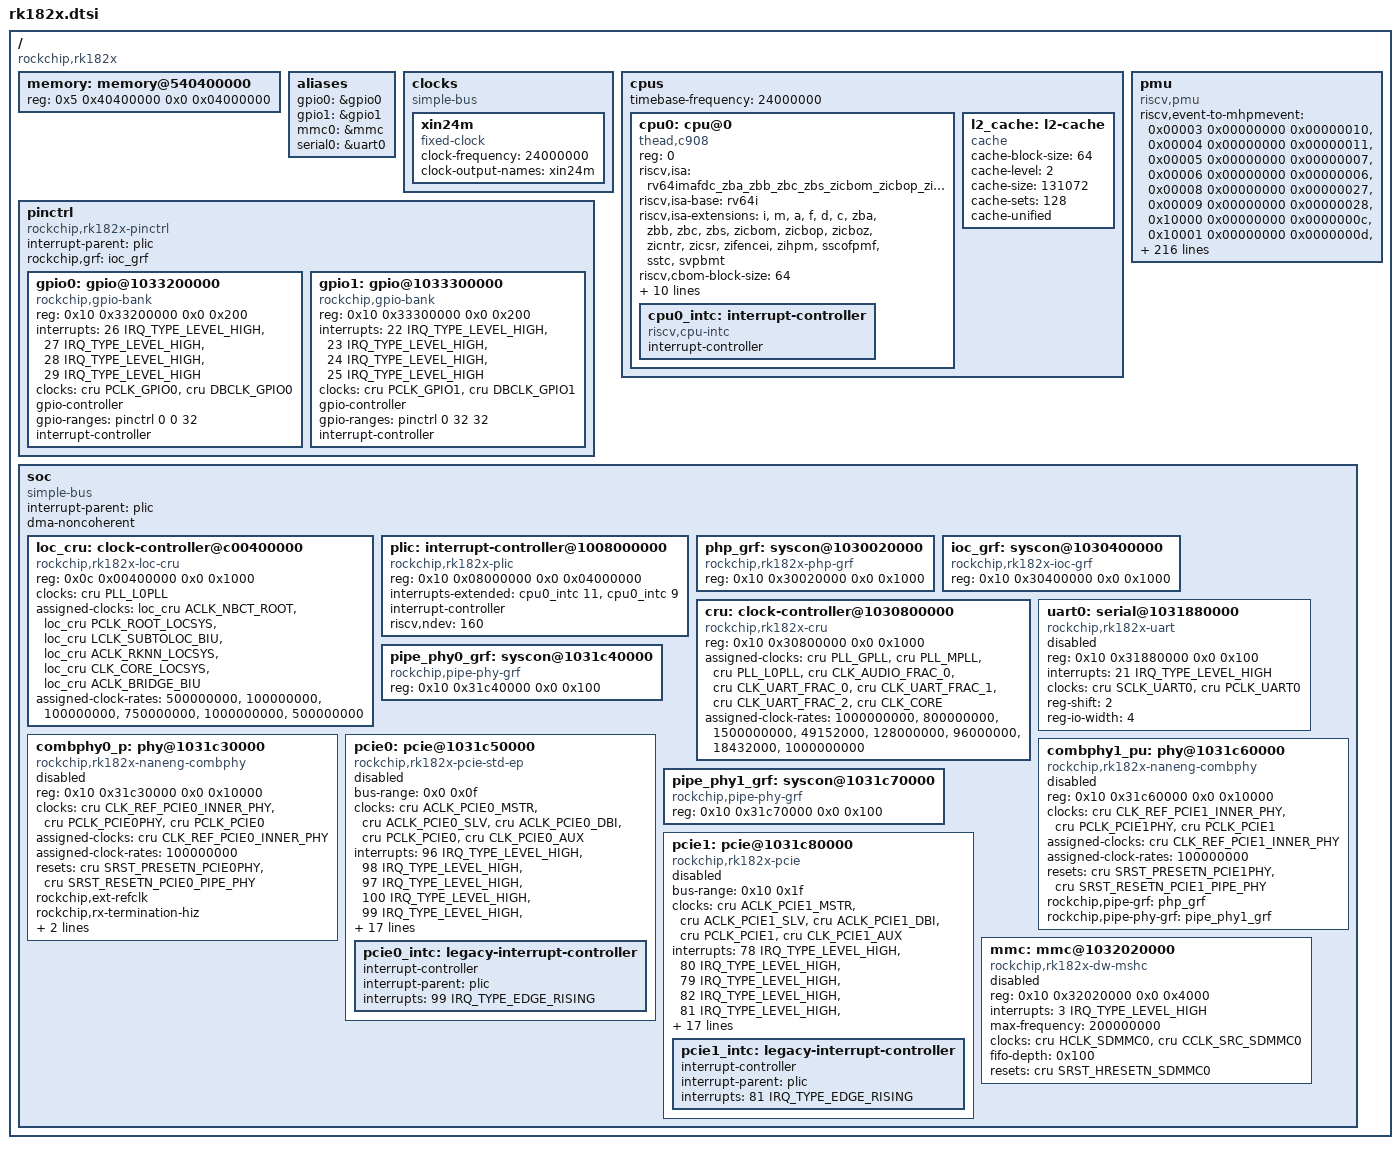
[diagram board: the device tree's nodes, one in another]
// SPDX-License-Identifier: (GPL-2.0+ OR MIT)
/*
 * Copyright (c) 2026 Rockchip Electronics Co., Ltd.
 */

#include <dt-bindings/clock/rockchip,rk182x-cru.h>
#include <dt-bindings/interrupt-controller/irq.h>
#include <dt-bindings/phy/phy.h>

/ {
	compatible = "rockchip,rk182x";

	#address-cells = <2>;
	#size-cells = <2>;

	memory: memory@540400000 {
		device_type = "memory";
		reg = <0x5 0x40400000 0x0 0x04000000>;
	};

	aliases {
		gpio0 = &gpio0;
		gpio1 = &gpio1;
		mmc0 = &mmc;
		serial0 = &uart0;
	};

	clocks: clocks {
		compatible = "simple-bus";
		#address-cells = <2>;
		#size-cells = <2>;
		ranges;

		xin24m: xin24m {
			compatible = "fixed-clock";
			#clock-cells = <0>;
			clock-frequency = <24000000>;
			clock-output-names = "xin24m";
		};
	};

	cpus: cpus {
		#address-cells = <1>;
		#size-cells = <0>;
		timebase-frequency = <24000000>;

		cpu0: cpu@0 {
			compatible = "thead,c908", "riscv";
			device_type = "cpu";
			reg = <0>;
			riscv,isa = "rv64imafdc_zba_zbb_zbc_zbs_zicbom_zicbop_zicboz_sscofpmf_sstc_svpbmt";
			riscv,isa-base = "rv64i";
			riscv,isa-extensions = "i", "m", "a", "f", "d", "c", "zba", "zbb",
					       "zbc", "zbs", "zicbom", "zicbop", "zicboz",
					       "zicntr", "zicsr", "zifencei", "zihpm",
					       "sscofpmf", "sstc", "svpbmt";
			riscv,cbom-block-size = <64>;
			riscv,cbop-block-size = <64>;
			riscv,cboz-block-size = <64>;
			d-cache-block-size = <64>;
			d-cache-sets = <128>;
			d-cache-size = <32768>;
			i-cache-block-size = <64>;
			i-cache-sets = <128>;
			i-cache-size = <32768>;
			next-level-cache = <&l2_cache>;
			mmu-type = "riscv,sv39";

			cpu0_intc: interrupt-controller {
				compatible = "riscv,cpu-intc";
				interrupt-controller;
				#interrupt-cells = <1>;
			};
		};

		l2_cache: l2-cache {
			compatible = "cache";
			cache-block-size = <64>;
			cache-level = <2>;
			cache-size = <131072>;
			cache-sets = <128>;
			cache-unified;
		};
	};

	pinctrl: pinctrl {
		compatible = "rockchip,rk182x-pinctrl";
		interrupt-parent = <&plic>;
		rockchip,grf = <&ioc_grf>;
		#address-cells = <2>;
		#size-cells = <2>;
		ranges;

		gpio0: gpio@1033200000 {
			compatible = "rockchip,gpio-bank";
			reg = <0x10 0x33200000 0x0 0x200>;
			interrupts = <26 IRQ_TYPE_LEVEL_HIGH>,
				     <27 IRQ_TYPE_LEVEL_HIGH>,
				     <28 IRQ_TYPE_LEVEL_HIGH>,
				     <29 IRQ_TYPE_LEVEL_HIGH>;
			clocks = <&cru PCLK_GPIO0>, <&cru DBCLK_GPIO0>;

			gpio-controller;
			#gpio-cells = <2>;
			gpio-ranges = <&pinctrl 0 0 32>;
			interrupt-controller;
			#interrupt-cells = <2>;
		};

		gpio1: gpio@1033300000 {
			compatible = "rockchip,gpio-bank";
			reg = <0x10 0x33300000 0x0 0x200>;
			interrupts = <22 IRQ_TYPE_LEVEL_HIGH>,
				     <23 IRQ_TYPE_LEVEL_HIGH>,
				     <24 IRQ_TYPE_LEVEL_HIGH>,
				     <25 IRQ_TYPE_LEVEL_HIGH>;
			clocks = <&cru PCLK_GPIO1>, <&cru DBCLK_GPIO1>;

			gpio-controller;
			#gpio-cells = <2>;
			gpio-ranges = <&pinctrl 0 32 32>;
			interrupt-controller;
			#interrupt-cells = <2>;
		};
	};

	pmu: pmu {
		compatible = "riscv,pmu";
		riscv,event-to-mhpmevent =
			/* PMU_HW_CACHE_REFERENCES -> ll_cache_read_access */
			<0x00003 0x00000000 0x00000010>,
			/* PMU_HW_CACHE_MISSES -> ll_cache_read_miss */
			<0x00004 0x00000000 0x00000011>,
			/* PMU_HW_BRANCH_INSTRUCTIONS -> inst_branch */
			<0x00005 0x00000000 0x00000007>,
			/* PMU_HW_BRANCH_MISSES -> inst_branch_mispredict */
			<0x00006 0x00000000 0x00000006>,
			/* PMU_HW_STALLED_CYCLES_FRONTEND -> ifu_stalled_cycle */
			<0x00008 0x00000000 0x00000027>,
			/* PMU_HW_STALLED_CYCLES_BACKEND -> idu_stalled_cycle */
			<0x00009 0x00000000 0x00000028>,
			/* L1D_READ_ACCESS -> l1_dcache_read_access */
			<0x10000 0x00000000 0x0000000c>,
			/* L1D_READ_MISS -> l1_dcache_read_miss */
			<0x10001 0x00000000 0x0000000d>,
			/* L1D_WRITE_ACCESS -> l1_dcache_write_access */
			<0x10002 0x00000000 0x0000000e>,
			/* L1D_WRITE_MISS -> l1_dcache_write_miss */
			<0x10003 0x00000000 0x0000000f>,
			/* L1I_READ_ACCESS -> l1_icache_access */
			<0x10008 0x00000000 0x00000001>,
			/* L1I_READ_MISS -> l1_icache_miss */
			<0x10009 0x00000000 0x00000002>,
			/* LL_READ_ACCESS -> ll_cache_read_access */
			<0x10010 0x00000000 0x00000010>,
			/* LL_READ_MISS -> ll_cache_read_miss */
			<0x10011 0x00000000 0x00000011>,
			/* LL_WRITE_ACCESS -> ll_cache_write_access */
			<0x10012 0x00000000 0x00000012>,
			/* LL_WRITE_MISS -> ll_cache_write_miss */
			<0x10013 0x00000000 0x00000013>,
			/* DTLB_READ_MISS -> dtlb_miss */
			<0x10019 0x00000000 0x00000004>,
			/* ITLB_READ_MISS -> itlb_miss */
			<0x10021 0x00000000 0x00000003>,
			/* BPU_READ_ACCESS -> branch_direction_prediction */
			<0x10030 0x00000000 0x0000001c>,
			/* BPU_READ_MISS -> branch_direction_misprediction */
			<0x10031 0x00000000 0x0000001b>;
		riscv,event-to-mhpmcounters =
			<0x00003 0x00003 0xfffffff8>,
			<0x00004 0x00004 0xfffffff8>,
			<0x00005 0x00005 0xfffffff8>,
			<0x00006 0x00006 0xfffffff8>,
			<0x00007 0x00007 0xfffffff8>,
			<0x00008 0x00008 0xfffffff8>,
			<0x00009 0x00009 0xfffffff8>,
			<0x0000a 0x0000a 0xfffffff8>,
			<0x10000 0x10000 0xfffffff8>,
			<0x10001 0x10001 0xfffffff8>,
			<0x10002 0x10002 0xfffffff8>,
			<0x10003 0x10003 0xfffffff8>,
			<0x10008 0x10008 0xfffffff8>,
			<0x10009 0x10009 0xfffffff8>,
			<0x10010 0x10010 0xfffffff8>,
			<0x10011 0x10011 0xfffffff8>,
			<0x10012 0x10012 0xfffffff8>,
			<0x10013 0x10013 0xfffffff8>,
			<0x10019 0x10019 0xfffffff8>,
			<0x10021 0x10021 0xfffffff8>,
			<0x10030 0x10030 0xfffffff8>,
			<0x10031 0x10031 0xfffffff8>;
		riscv,raw-event-to-mhpmcounters =
			<0x00000000 0x00000001 0xffffffff 0xffffffff 0xfffffff8>,
			<0x00000000 0x00000002 0xffffffff 0xffffffff 0xfffffff8>,
			<0x00000000 0x00000003 0xffffffff 0xffffffff 0xfffffff8>,
			<0x00000000 0x00000004 0xffffffff 0xffffffff 0xfffffff8>,
			<0x00000000 0x00000005 0xffffffff 0xffffffff 0xfffffff8>,
			<0x00000000 0x00000006 0xffffffff 0xffffffff 0xfffffff8>,
			<0x00000000 0x00000007 0xffffffff 0xffffffff 0xfffffff8>,
			<0x00000000 0x00000008 0xffffffff 0xffffffff 0xfffffff8>,
			<0x00000000 0x00000009 0xffffffff 0xffffffff 0xfffffff8>,
			<0x00000000 0x0000000a 0xffffffff 0xffffffff 0xfffffff8>,
			<0x00000000 0x0000000b 0xffffffff 0xffffffff 0xfffffff8>,
			<0x00000000 0x0000000c 0xffffffff 0xffffffff 0xfffffff8>,
			<0x00000000 0x0000000d 0xffffffff 0xffffffff 0xfffffff8>,
			<0x00000000 0x0000000e 0xffffffff 0xffffffff 0xfffffff8>,
			<0x00000000 0x0000000f 0xffffffff 0xffffffff 0xfffffff8>,
			<0x00000000 0x00000010 0xffffffff 0xffffffff 0xfffffff8>,
			<0x00000000 0x00000011 0xffffffff 0xffffffff 0xfffffff8>,
			<0x00000000 0x00000012 0xffffffff 0xffffffff 0xfffffff8>,
			<0x00000000 0x00000013 0xffffffff 0xffffffff 0xfffffff8>,
			<0x00000000 0x00000014 0xffffffff 0xffffffff 0xfffffff8>,
			<0x00000000 0x00000015 0xffffffff 0xffffffff 0xfffffff8>,
			<0x00000000 0x00000016 0xffffffff 0xffffffff 0xfffffff8>,
			<0x00000000 0x00000017 0xffffffff 0xffffffff 0xfffffff8>,
			<0x00000000 0x00000018 0xffffffff 0xffffffff 0xfffffff8>,
			<0x00000000 0x00000019 0xffffffff 0xffffffff 0xfffffff8>,
			<0x00000000 0x0000001a 0xffffffff 0xffffffff 0xfffffff8>,
			<0x00000000 0x0000001b 0xffffffff 0xffffffff 0xfffffff8>,
			<0x00000000 0x0000001c 0xffffffff 0xffffffff 0xfffffff8>,
			<0x00000000 0x0000001d 0xffffffff 0xffffffff 0xfffffff8>,
			<0x00000000 0x0000001e 0xffffffff 0xffffffff 0xfffffff8>,
			<0x00000000 0x0000001f 0xffffffff 0xffffffff 0xfffffff8>,
			<0x00000000 0x00000020 0xffffffff 0xffffffff 0xfffffff8>,
			<0x00000000 0x00000021 0xffffffff 0xffffffff 0xfffffff8>,
			<0x00000000 0x00000022 0xffffffff 0xffffffff 0xfffffff8>,
			<0x00000000 0x00000023 0xffffffff 0xffffffff 0xfffffff8>,
			<0x00000000 0x00000024 0xffffffff 0xffffffff 0xfffffff8>,
			<0x00000000 0x00000025 0xffffffff 0xffffffff 0xfffffff8>,
			<0x00000000 0x00000026 0xffffffff 0xffffffff 0xfffffff8>,
			<0x00000000 0x00000027 0xffffffff 0xffffffff 0xfffffff8>,
			<0x00000000 0x00000028 0xffffffff 0xffffffff 0xfffffff8>,
			<0x00000000 0x00000029 0xffffffff 0xffffffff 0xfffffff8>,
			<0x00000000 0x0000002a 0xffffffff 0xffffffff 0xfffffff8>,
			<0x00000000 0x0000002b 0xffffffff 0xffffffff 0xfffffff8>,
			<0x00000000 0x0000002c 0xffffffff 0xffffffff 0xfffffff8>,
			<0x00000000 0x0000002d 0xffffffff 0xffffffff 0xfffffff8>,
			<0x00000000 0x0000002e 0xffffffff 0xffffffff 0xfffffff8>,
			<0x00000000 0x0000002f 0xffffffff 0xffffffff 0xfffffff8>,
			<0x00000000 0x00000030 0xffffffff 0xffffffff 0xfffffff8>,
			<0x00000000 0x00000031 0xffffffff 0xffffffff 0xfffffff8>,
			<0x00000000 0x00000032 0xffffffff 0xffffffff 0xfffffff8>,
			<0x00000000 0x00000033 0xffffffff 0xffffffff 0xfffffff8>,
			<0x00000000 0x00000034 0xffffffff 0xffffffff 0xfffffff8>,
			<0x00000000 0x00000035 0xffffffff 0xffffffff 0xfffffff8>,
			<0x00000000 0x00000036 0xffffffff 0xffffffff 0xfffffff8>,
			<0x00000000 0x00000037 0xffffffff 0xffffffff 0xfffffff8>,
			<0x00000000 0x00000038 0xffffffff 0xffffffff 0xfffffff8>,
			<0x00000000 0x00000039 0xffffffff 0xffffffff 0xfffffff8>,
			<0x00000000 0x0000003a 0xffffffff 0xffffffff 0xfffffff8>,
			<0x00000000 0x0000003b 0xffffffff 0xffffffff 0xfffffff8>,
			<0x00000000 0x0000003c 0xffffffff 0xffffffff 0xfffffff8>,
			<0x00000000 0x0000003d 0xffffffff 0xffffffff 0xfffffff8>,
			<0x00000000 0x0000003e 0xffffffff 0xffffffff 0xfffffff8>,
			<0x00000000 0x0000003f 0xffffffff 0xffffffff 0xfffffff8>,
			<0x00000000 0x00000040 0xffffffff 0xffffffff 0xfffffff8>,
			<0x00000000 0x00000041 0xffffffff 0xffffffff 0xfffffff8>,
			<0x00000000 0x00000042 0xffffffff 0xffffffff 0xfffffff8>,
			<0x00000000 0x00000043 0xffffffff 0xffffffff 0xfffffff8>,
			<0x00000000 0x00000044 0xffffffff 0xffffffff 0xfffffff8>,
			<0x00000000 0x00000045 0xffffffff 0xffffffff 0xfffffff8>,
			<0x00000000 0x00000046 0xffffffff 0xffffffff 0xfffffff8>,
			<0x00000000 0x00000047 0xffffffff 0xffffffff 0xfffffff8>,
			<0x00000000 0x00000048 0xffffffff 0xffffffff 0xfffffff8>,
			<0x00000000 0x00000049 0xffffffff 0xffffffff 0xfffffff8>,
			<0x00000000 0x0000004a 0xffffffff 0xffffffff 0xfffffff8>,
			<0x00000000 0x0000004b 0xffffffff 0xffffffff 0xfffffff8>,
			<0x00000000 0x0000004c 0xffffffff 0xffffffff 0xfffffff8>,
			<0x00000000 0x0000004d 0xffffffff 0xffffffff 0xfffffff8>,
			<0x00000000 0x0000004e 0xffffffff 0xffffffff 0xfffffff8>,
			<0x00000000 0x0000004f 0xffffffff 0xffffffff 0xfffffff8>,
			<0x00000000 0x00000050 0xffffffff 0xffffffff 0xfffffff8>,
			<0x00000000 0x00000051 0xffffffff 0xffffffff 0xfffffff8>,
			<0x00000000 0x00000052 0xffffffff 0xffffffff 0xfffffff8>,
			<0x00000000 0x00000053 0xffffffff 0xffffffff 0xfffffff8>,
			<0x00000000 0x00000054 0xffffffff 0xffffffff 0xfffffff8>,
			<0x00000000 0x00000055 0xffffffff 0xffffffff 0xfffffff8>,
			<0x00000000 0x00000056 0xffffffff 0xffffffff 0xfffffff8>,
			<0x00000000 0x00000057 0xffffffff 0xffffffff 0xfffffff8>,
			<0x00000000 0x00000058 0xffffffff 0xffffffff 0xfffffff8>,
			<0x00000000 0x00000059 0xffffffff 0xffffffff 0xfffffff8>,
			<0x00000000 0x0000005a 0xffffffff 0xffffffff 0xfffffff8>,
			<0x00000000 0x0000005b 0xffffffff 0xffffffff 0xfffffff8>,
			<0x00000000 0x0000005c 0xffffffff 0xffffffff 0xfffffff8>,
			<0x00000000 0x0000005d 0xffffffff 0xffffffff 0xfffffff8>,
			<0x00000000 0x0000005e 0xffffffff 0xffffffff 0xfffffff8>,
			<0x00000000 0x0000005f 0xffffffff 0xffffffff 0xfffffff8>,
			<0x00000000 0x00000060 0xffffffff 0xffffffff 0xfffffff8>,
			<0x00000000 0x00000061 0xffffffff 0xffffffff 0xfffffff8>,
			<0x00000000 0x00000062 0xffffffff 0xffffffff 0xfffffff8>,
			<0x00000000 0x00000063 0xffffffff 0xffffffff 0xfffffff8>,
			<0x00000000 0x00000064 0xffffffff 0xffffffff 0xfffffff8>,
			<0x00000000 0x00000065 0xffffffff 0xffffffff 0xfffffff8>,
			<0x00000000 0x00000066 0xffffffff 0xffffffff 0xfffffff8>,
			<0x00000000 0x00000067 0xffffffff 0xffffffff 0xfffffff8>,
			<0x00000000 0x00000068 0xffffffff 0xffffffff 0xfffffff8>,
			<0x00000000 0x00000069 0xffffffff 0xffffffff 0xfffffff8>,
			<0x00000000 0x0000006a 0xffffffff 0xffffffff 0xfffffff8>,
			<0x00000000 0x0000006b 0xffffffff 0xffffffff 0xfffffff8>,
			<0x00000000 0x0000006c 0xffffffff 0xffffffff 0xfffffff8>,
			<0x00000000 0x0000006d 0xffffffff 0xffffffff 0xfffffff8>,
			<0x00000000 0x0000006e 0xffffffff 0xffffffff 0xfffffff8>,
			<0x00000000 0x0000006f 0xffffffff 0xffffffff 0xfffffff8>,
			<0x00000000 0x00000070 0xffffffff 0xffffffff 0xfffffff8>,
			<0x00000000 0x00000071 0xffffffff 0xffffffff 0xfffffff8>,
			<0x00000000 0x00000072 0xffffffff 0xffffffff 0xfffffff8>,
			<0x00000000 0x00000073 0xffffffff 0xffffffff 0xfffffff8>,
			<0x00000000 0x00000074 0xffffffff 0xffffffff 0xfffffff8>,
			<0x00000000 0x00000075 0xffffffff 0xffffffff 0xfffffff8>,
			<0x00000000 0x00000076 0xffffffff 0xffffffff 0xfffffff8>,
			<0x00000000 0x00000077 0xffffffff 0xffffffff 0xfffffff8>,
			<0x00000000 0x00000078 0xffffffff 0xffffffff 0xfffffff8>,
			<0x00000000 0x00000079 0xffffffff 0xffffffff 0xfffffff8>,
			<0x00000000 0x0000007a 0xffffffff 0xffffffff 0xfffffff8>,
			<0x00000000 0x0000007b 0xffffffff 0xffffffff 0xfffffff8>,
			<0x00000000 0x0000007c 0xffffffff 0xffffffff 0xfffffff8>,
			<0x00000000 0x0000007d 0xffffffff 0xffffffff 0xfffffff8>,
			<0x00000000 0x0000007e 0xffffffff 0xffffffff 0xfffffff8>,
			<0x00000000 0x0000007f 0xffffffff 0xffffffff 0xfffffff8>,
			<0x00000000 0x00000080 0xffffffff 0xffffffff 0xfffffff8>,
			<0x00000000 0x00000081 0xffffffff 0xffffffff 0xfffffff8>,
			<0x00000000 0x00000082 0xffffffff 0xffffffff 0xfffffff8>,
			<0x00000000 0x00000083 0xffffffff 0xffffffff 0xfffffff8>,
			<0x00000000 0x00000084 0xffffffff 0xffffffff 0xfffffff8>,
			<0x00000000 0x00000085 0xffffffff 0xffffffff 0xfffffff8>,
			<0x00000000 0x00000086 0xffffffff 0xffffffff 0xfffffff8>,
			<0x00000000 0x00000087 0xffffffff 0xffffffff 0xfffffff8>,
			<0x00000000 0x00000088 0xffffffff 0xffffffff 0xfffffff8>,
			<0x00000000 0x00000089 0xffffffff 0xffffffff 0xfffffff8>,
			<0x00000000 0x0000008a 0xffffffff 0xffffffff 0xfffffff8>,
			<0x00000000 0x0000008b 0xffffffff 0xffffffff 0xfffffff8>,
			<0x00000000 0x0000008c 0xffffffff 0xffffffff 0xfffffff8>,
			<0x00000000 0x0000008d 0xffffffff 0xffffffff 0xfffffff8>,
			<0x00000000 0x0000008e 0xffffffff 0xffffffff 0xfffffff8>,
			<0x00000000 0x0000008f 0xffffffff 0xffffffff 0xfffffff8>,
			<0x00000000 0x00000090 0xffffffff 0xffffffff 0xfffffff8>,
			<0x00000000 0x00000091 0xffffffff 0xffffffff 0xfffffff8>,
			<0x00000000 0x00000092 0xffffffff 0xffffffff 0xfffffff8>,
			<0x00000000 0x00000093 0xffffffff 0xffffffff 0xfffffff8>,
			<0x00000000 0x00000094 0xffffffff 0xffffffff 0xfffffff8>,
			<0x00000000 0x00000095 0xffffffff 0xffffffff 0xfffffff8>,
			<0x00000000 0x00000096 0xffffffff 0xffffffff 0xfffffff8>,
			<0x00000000 0x00000097 0xffffffff 0xffffffff 0xfffffff8>,
			<0x00000000 0x00000098 0xffffffff 0xffffffff 0xfffffff8>,
			<0x00000000 0x00000099 0xffffffff 0xffffffff 0xfffffff8>,
			<0x00000000 0x0000009a 0xffffffff 0xffffffff 0xfffffff8>,
			<0x00000000 0x0000009b 0xffffffff 0xffffffff 0xfffffff8>,
			<0x00000000 0x0000009c 0xffffffff 0xffffffff 0xfffffff8>,
			<0x00000000 0x0000009d 0xffffffff 0xffffffff 0xfffffff8>,
			<0x00000000 0x0000009e 0xffffffff 0xffffffff 0xfffffff8>,
			<0x00000000 0x0000009f 0xffffffff 0xffffffff 0xfffffff8>,
			<0x00000000 0x000000a0 0xffffffff 0xffffffff 0xfffffff8>,
			<0x00000000 0x000000a1 0xffffffff 0xffffffff 0xfffffff8>,
			<0x00000000 0x000000a2 0xffffffff 0xffffffff 0xfffffff8>,
			<0x00000000 0x000000a3 0xffffffff 0xffffffff 0xfffffff8>,
			<0x00000000 0x000000a4 0xffffffff 0xffffffff 0xfffffff8>,
			<0x00000000 0x000000a5 0xffffffff 0xffffffff 0xfffffff8>,
			<0x00000000 0x000000a6 0xffffffff 0xffffffff 0xfffffff8>,
			<0x00000000 0x000000a7 0xffffffff 0xffffffff 0xfffffff8>,
			<0x00000000 0x000000a8 0xffffffff 0xffffffff 0xfffffff8>,
			<0x00000000 0x000000a9 0xffffffff 0xffffffff 0xfffffff8>,
			<0x00000000 0x000000aa 0xffffffff 0xffffffff 0xfffffff8>,
			<0x00000000 0x000000ab 0xffffffff 0xffffffff 0xfffffff8>,
			<0x00000000 0x000000ac 0xffffffff 0xffffffff 0xfffffff8>,
			<0x00000000 0x000000ad 0xffffffff 0xffffffff 0xfffffff8>,
			<0x00000000 0x000000ae 0xffffffff 0xffffffff 0xfffffff8>,
			<0x00000000 0x000000af 0xffffffff 0xffffffff 0xfffffff8>,
			<0x00000000 0x000000b0 0xffffffff 0xffffffff 0xfffffff8>,
			<0x00000000 0x000000b1 0xffffffff 0xffffffff 0xfffffff8>,
			<0x00000000 0x000000b2 0xffffffff 0xffffffff 0xfffffff8>,
			<0x00000000 0x000000b3 0xffffffff 0xffffffff 0xfffffff8>,
			<0x00000000 0x000000b4 0xffffffff 0xffffffff 0xfffffff8>;
	};

	soc: soc {
		compatible = "simple-bus";
		interrupt-parent = <&plic>;
		#address-cells = <2>;
		#size-cells = <2>;
		dma-noncoherent;
		ranges;

		loc_cru: clock-controller@c00400000 {
			compatible = "rockchip,rk182x-loc-cru";
			reg = <0x0c 0x00400000 0x0 0x1000>;
			#clock-cells = <1>;
			#reset-cells = <1>;
			clocks = <&cru PLL_L0PLL>;

			assigned-clocks =
				<&loc_cru ACLK_NBCT_ROOT>, <&loc_cru PCLK_ROOT_LOCSYS>,
				<&loc_cru LCLK_SUBTOLOC_BIU>, <&loc_cru ACLK_RKNN_LOCSYS>,
				<&loc_cru CLK_CORE_LOCSYS>, <&loc_cru ACLK_BRIDGE_BIU>;
			assigned-clock-rates =
				<500000000>, <100000000>,
				<100000000>, <750000000>,
				<1000000000>, <500000000>;
		};

		plic: interrupt-controller@1008000000 {
			compatible = "rockchip,rk182x-plic", "thead,c900-plic";
			reg = <0x10 0x08000000 0x0 0x04000000>;
			interrupts-extended = <&cpu0_intc 11>, <&cpu0_intc 9>;
			interrupt-controller;
			#address-cells = <0>;
			#interrupt-cells = <2>;
			riscv,ndev = <160>;
		};

		php_grf: syscon@1030020000 {
			compatible = "rockchip,rk182x-php-grf", "syscon";
			reg = <0x10 0x30020000 0x0 0x1000>;
		};

		ioc_grf: syscon@1030400000 {
			compatible = "rockchip,rk182x-ioc-grf", "syscon";
			reg = <0x10 0x30400000 0x0 0x1000>;
		};

		cru: clock-controller@1030800000 {
			compatible = "rockchip,rk182x-cru";
			reg = <0x10 0x30800000 0x0 0x1000>;
			#clock-cells = <1>;
			#reset-cells = <1>;

			assigned-clocks =
				<&cru PLL_GPLL>, <&cru PLL_MPLL>,
				<&cru PLL_L0PLL>, <&cru CLK_AUDIO_FRAC_0>,
				<&cru CLK_UART_FRAC_0>, <&cru CLK_UART_FRAC_1>,
				<&cru CLK_UART_FRAC_2>, <&cru CLK_CORE>;
			assigned-clock-rates =
				<1000000000>, <800000000>,
				<1500000000>, <49152000>,
				<128000000>, <96000000>,
				<18432000>, <1000000000>;
		};

		uart0: serial@1031880000 {
			compatible = "rockchip,rk182x-uart", "snps,dw-apb-uart";
			reg = <0x10 0x31880000 0x0 0x100>;
			interrupts = <21 IRQ_TYPE_LEVEL_HIGH>;
			clocks = <&cru SCLK_UART0>, <&cru PCLK_UART0>;
			clock-names = "baudclk", "apb_pclk";
			reg-shift = <2>;
			reg-io-width = <4>;
			status = "disabled";
		};

		combphy0_p: phy@1031c30000 {
			compatible = "rockchip,rk182x-naneng-combphy";
			reg = <0x10 0x31c30000 0x0 0x10000>;
			#phy-cells = <1>;
			clocks = <&cru CLK_REF_PCIE0_INNER_PHY>,
				 <&cru PCLK_PCIE0PHY>,
				 <&cru PCLK_PCIE0>;
			clock-names = "refclk", "apbclk", "pipe_clk";
			assigned-clocks = <&cru CLK_REF_PCIE0_INNER_PHY>;
			assigned-clock-rates = <100000000>;
			resets = <&cru SRST_PRESETN_PCIE0PHY>,
				 <&cru SRST_RESETN_PCIE0_PIPE_PHY>;
			reset-names = "combphy-apb", "combphy";
			rockchip,ext-refclk;
			rockchip,rx-termination-hiz;
			rockchip,pipe-grf = <&php_grf>;
			rockchip,pipe-phy-grf = <&pipe_phy0_grf>;
			status = "disabled";
		};

		pipe_phy0_grf: syscon@1031c40000 {
			compatible = "rockchip,pipe-phy-grf", "syscon";
			reg = <0x10 0x31c40000 0x0 0x100>;
		};

		pcie0: pcie@1031c50000 {
			compatible = "rockchip,rk182x-pcie-std-ep", "rockchip,rk3568-pcie-std-ep";
			#address-cells = <3>;
			#size-cells = <2>;
			bus-range = <0x0 0x0f>;
			clocks = <&cru ACLK_PCIE0_MSTR>, <&cru ACLK_PCIE0_SLV>,
				 <&cru ACLK_PCIE0_DBI>, <&cru PCLK_PCIE0>,
				 <&cru CLK_PCIE0_AUX>;
			clock-names = "aclk_mst", "aclk_slv",
				      "aclk_dbi", "pclk",
				      "aux";
			device_type = "pci";
			interrupts = <96 IRQ_TYPE_LEVEL_HIGH>,
				     <98 IRQ_TYPE_LEVEL_HIGH>,
				     <97 IRQ_TYPE_LEVEL_HIGH>,
				     <100 IRQ_TYPE_LEVEL_HIGH>,
				     <99 IRQ_TYPE_LEVEL_HIGH>,
				     <101 IRQ_TYPE_LEVEL_HIGH>;
			interrupt-names = "msi", "sys", "pmc", "msg", "legacy", "err";
			#interrupt-cells = <1>;
			interrupt-map-mask = <0 0 0 7>;
			interrupt-map = <0 0 0 1 &pcie0_intc 0>,
					<0 0 0 2 &pcie0_intc 1>,
					<0 0 0 3 &pcie0_intc 2>,
					<0 0 0 4 &pcie0_intc 3>;
			linux,pci-domain = <0>;
			num-ib-windows = <16>;
			num-ob-windows = <16>;
			num-viewport = <16>;
			max-link-speed = <2>;
			num-lanes = <1>;
			phys = <&combphy0_p PHY_TYPE_PCIE>;
			phy-names = "pcie-phy";
			ranges = <0x00000800 0x00 0x10000000 0x10 0x10000000 0x0 0x00100000
				  0x81000000 0x00 0x10100000 0x10 0x10100000 0x0 0x00100000
				  0x82000000 0x00 0x10200000 0x10 0x10200000 0x0 0x07e00000
				  0x83000000 0x11 0x00000000 0x11 0x00000000 0x0 0x80000000>;
			reg = <0x10 0x31c50000 0x0 0x00010000>,
			      <0x10 0x21000000 0x0 0x00400000>,
			      <0x10 0x10000000 0x0 0x00100000>;
			reg-names = "pcie-apb", "pcie-dbi", "config";
			resets = <&cru SRST_RESETN_PCIE0_POWER_UP>, <&cru SRST_PRESETN_PCIE0>;
			reset-names = "pipe", "p_pcie";
			status = "disabled";

			pcie0_intc: legacy-interrupt-controller {
				interrupt-controller;
				#address-cells = <0>;
				#interrupt-cells = <1>;
				interrupt-parent = <&plic>;
				interrupts = <99 IRQ_TYPE_EDGE_RISING>;
			};
		};

		combphy1_pu: phy@1031c60000 {
			compatible = "rockchip,rk182x-naneng-combphy";
			reg = <0x10 0x31c60000 0x0 0x10000>;
			#phy-cells = <1>;
			clocks = <&cru CLK_REF_PCIE1_INNER_PHY>,
				 <&cru PCLK_PCIE1PHY>,
				 <&cru PCLK_PCIE1>;
			clock-names = "refclk", "apbclk", "pipe_clk";
			assigned-clocks = <&cru CLK_REF_PCIE1_INNER_PHY>;
			assigned-clock-rates = <100000000>;
			resets = <&cru SRST_PRESETN_PCIE1PHY>,
				 <&cru SRST_RESETN_PCIE1_PIPE_PHY>;
			reset-names = "combphy-apb", "combphy";
			rockchip,pipe-grf = <&php_grf>;
			rockchip,pipe-phy-grf = <&pipe_phy1_grf>;
			status = "disabled";
		};

		pipe_phy1_grf: syscon@1031c70000 {
			compatible = "rockchip,pipe-phy-grf", "syscon";
			reg = <0x10 0x31c70000 0x0 0x100>;
		};

		pcie1: pcie@1031c80000 {
			compatible = "rockchip,rk182x-pcie", "rockchip,rk3568-pcie";
			#address-cells = <3>;
			#size-cells = <2>;
			bus-range = <0x10 0x1f>;
			clocks = <&cru ACLK_PCIE1_MSTR>, <&cru ACLK_PCIE1_SLV>,
				 <&cru ACLK_PCIE1_DBI>, <&cru PCLK_PCIE1>,
				 <&cru CLK_PCIE1_AUX>;
			clock-names = "aclk_mst", "aclk_slv",
				      "aclk_dbi", "pclk",
				      "aux";
			device_type = "pci";
			interrupts = <78 IRQ_TYPE_LEVEL_HIGH>,
				     <80 IRQ_TYPE_LEVEL_HIGH>,
				     <79 IRQ_TYPE_LEVEL_HIGH>,
				     <82 IRQ_TYPE_LEVEL_HIGH>,
				     <81 IRQ_TYPE_LEVEL_HIGH>,
				     <83 IRQ_TYPE_LEVEL_HIGH>;
			interrupt-names = "msi", "sys", "pmc", "msg", "legacy", "err";
			#interrupt-cells = <1>;
			interrupt-map-mask = <0 0 0 7>;
			interrupt-map = <0 0 0 1 &pcie1_intc 0>,
					<0 0 0 2 &pcie1_intc 1>,
					<0 0 0 3 &pcie1_intc 2>,
					<0 0 0 4 &pcie1_intc 3>;
			linux,pci-domain = <0>;
			num-ib-windows = <16>;
			num-ob-windows = <16>;
			num-viewport = <16>;
			max-link-speed = <2>;
			num-lanes = <1>;
			phys = <&combphy1_pu PHY_TYPE_PCIE>;
			phy-names = "pcie-phy";
			ranges = <0x00000800 0x00 0x18000000 0x10 0x18000000 0x0 0x00100000
				  0x81000000 0x00 0x18100000 0x10 0x18100000 0x0 0x00100000
				  0x82000000 0x00 0x18200000 0x10 0x18200000 0x0 0x07e00000
				  0x83000000 0x11 0x80000000 0x11 0x80000000 0x0 0x80000000>;
			reg = <0x10 0x31c80000 0x0 0x00010000>,
			      <0x10 0x23000000 0x0 0x00400000>,
			      <0x10 0x18000000 0x0 0x00100000>;
			reg-names = "pcie-apb", "pcie-dbi", "config";
			resets = <&cru SRST_RESETN_PCIE1_POWER_UP>, <&cru SRST_PRESETN_PCIE1>;
			reset-names = "pipe", "p_pcie";
			status = "disabled";

			pcie1_intc: legacy-interrupt-controller {
				interrupt-controller;
				#address-cells = <0>;
				#interrupt-cells = <1>;
				interrupt-parent = <&plic>;
				interrupts = <81 IRQ_TYPE_EDGE_RISING>;
			};
		};

		mmc: mmc@1032020000 {
			compatible = "rockchip,rk182x-dw-mshc", "rockchip,rk3576-dw-mshc";
			reg = <0x10 0x32020000 0x0 0x4000>;
			interrupts = <3 IRQ_TYPE_LEVEL_HIGH>;
			max-frequency = <200000000>;
			clocks = <&cru HCLK_SDMMC0>, <&cru CCLK_SRC_SDMMC0>;
			clock-names = "biu", "ciu";
			fifo-depth = <0x100>;
			resets = <&cru SRST_HRESETN_SDMMC0>;
			reset-names = "reset";
			status = "disabled";
		};
	};
};

#include "rk182x-pinctrl.dtsi"
